# S32K118 register map
Vendor: NXP; Series: S32K; File version: 1.6
CPU: CM0PLUS r0p0, little endian, MPU, FPU, 2 interrupt priority bits
Registers are 32-bit, read-write, reset 0x0 unless marked. A register's access mark holds for its fields unless they carry their own. Offsets are from the block's base; [hi:lo] are bit positions; {n}, {i} and the like mark numbered series; 'fields as' and 'values as' point back to an identical list.

## CSE_PRAM
Base 0x14000800; register names take the prefix CSE_PRAM
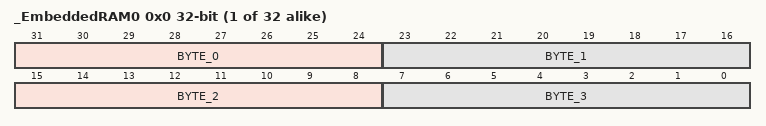
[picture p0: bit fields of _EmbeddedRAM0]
{0x0+4i} _EmbeddedRAM{i} (CSE_PRAM view) (i=0..31) — CSE PRAM {i} Register
  [31-8n:24-8n] BYTE_{n} (n=0..3) — Data byte {n} of Rx/Tx frame.
{0x0+4i} _EmbeddedRAM{i}LL 8-bit (CSE_PRAM view) (i=0..31) — CSE PRAM{i}LL register.
  [7:0] RAM_LL — RAM_LL stores the first 8 bits of the 32 bit CRC
{0x1+4i} _EmbeddedRAM{i}LU 8-bit (i=0..31) — CSE PRAM{i}LU register.
  [7:0] RAM_LU — RAM_LU stores the second 8 bits of the 32 bit CRC
{0x2+4i} _EmbeddedRAM{i}HL 8-bit (i=0..31) — CSE PRAM{i}HL register.
  [7:0] RAM_HL — RAM_HL stores the third 8 bits of the 32 bit CRC
{0x3+4i} _EmbeddedRAM{i}HU 8-bit (i=0..31) — CSE PRAM{i}HU register.
  [7:0] RAM_HU — RAM_HU stores the fourth 8 bits of the 32 bit CRC

## ERM
Base 0x40018000; register names take the prefix ERM_
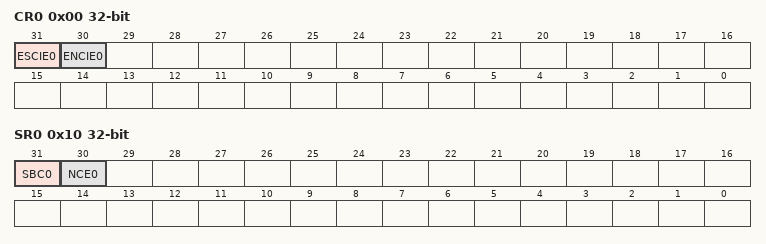
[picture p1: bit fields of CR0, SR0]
0x00 CR0 — ERM Configuration Register 0
  [31] ESCIE0
    0=Interrupt notification of Memory 0 single-bit correction events is disabled; 1=Interrupt notification of Memory 0 single-bit correction events is enabled
  [30] ENCIE0
    0=Interrupt notification of Memory 0 non-correctable error events is disabled; 1=Interrupt notification of Memory 0 non-correctable error events is enabled
0x10 SR0 — ERM Status Register 0
  [31] SBC0
    0=No single-bit correction event on Memory 0 detected; 1=Single-bit correction event on Memory 0 detected
  [30] NCE0
    0=No non-correctable error event on Memory 0 detected; 1=Non-correctable error event on Memory 0 detected
0x100 EAR0 ro — ERM Memory n Error Address Register
  [31:0] EAR

## EIM — Error Injection Module
Base 0x40019000; register names take the prefix EIM_
0x00 EIMCR — Error Injection Module Configuration Register
  [0] GEIEN — Global Error Injection Enable
    0=Disabled; 1=Enabled
0x04 EICHEN — Error Injection Channel Enable register
  [31] EICH0EN — Error Injection Channel 0 Enable
    0=Error injection is disabled on Error Injection Channel 0; 1=Error injection is enabled on Error Injection Channel 0
0x100 EICHD0_WORD0 — Error Injection Channel Descriptor n, Word0
  [31:25] CHKBIT_MASK — Checkbit Mask
0x104 EICHD0_WORD1 — Error Injection Channel Descriptor n, Word1
  [31:0] B0_3DATA_MASK — Data Mask Bytes 0-3

## DMAMUX — DMA channel multiplexor
Base 0x40021000; register names take the prefix DMAMUX_
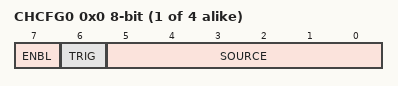
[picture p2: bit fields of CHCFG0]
{0x0+i} CHCFG{i} 8-bit (i=0..3) — Channel Configuration register
  [7] ENBL — DMA Channel Enable
    0=DMA channel is disabled. This mode is primarily used during configuration of the DMAMux. The DMA has separate channel enables/disables, which should be used to disable or reconfigure a DMA channel.; 1=DMA channel is enabled
  [6] TRIG — DMA Channel Trigger Enable
    0=Triggering is disabled. If triggering is disabled and ENBL is set, the DMA Channel will simply route the specified source to the DMA channel. (Normal mode); 1=Triggering is enabled. If triggering is enabled and ENBL is set, the DMAMUX is in Periodic Trigger mode.
  [5:0] SOURCE — DMA Channel Source (Slot)

## CRC — Cyclic Redundancy Check
Base 0x40032000; register names take the prefix CRC_
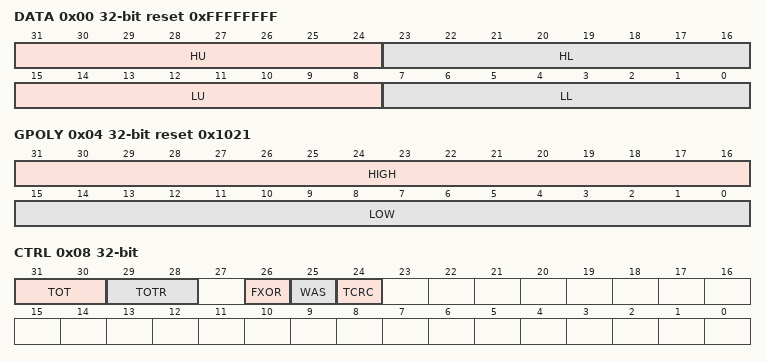
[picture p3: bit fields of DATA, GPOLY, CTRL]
0x00 DATA reset 0xFFFFFFFF (CRC view) — CRC Data register
  [31:24] HU — CRC High Upper Byte
  [23:16] HL — CRC High Lower Byte
  [15:8] LU — CRC Low Upper Byte
  [7:0] LL — CRC Low Lower Byte
0x00 DATAL 16-bit reset 0xFFFF (CRC view) — CRC_DATAL register.
  [15:0] DATAL — DATAL stores the lower 16 bits of the 16/32 bit CRC
0x00 DATALL 8-bit reset 0xFF (CRC view) — CRC_DATALL register.
  [7:0] DATALL — CRCLL stores the first 8 bits of the 32 bit DATA
0x01 DATALU 8-bit reset 0xFF — CRC_DATALU register.
  [7:0] DATALU — DATALL stores the second 8 bits of the 32 bit CRC
0x02 DATAH 16-bit reset 0xFFFF (CRC view) — CRC_DATAH register.
  [15:0] DATAH — DATAH stores the high 16 bits of the 16/32 bit CRC
0x02 DATAHL 8-bit reset 0xFF (CRC view) — CRC_DATAHL register.
  [7:0] DATAHL — DATAHL stores the third 8 bits of the 32 bit CRC
0x03 DATAHU 8-bit reset 0xFF — CRC_DATAHU register.
  [7:0] DATAHU — DATAHU stores the fourth 8 bits of the 32 bit CRC
0x04 GPOLY reset 0x1021 — CRC Polynomial register
  [31:16] HIGH — High Polynominal Half-word
  [15:0] LOW — Low Polynominal Half-word
0x08 CTRL — CRC Control register
  [31:30] TOT — Type Of Transpose For Writes
    0=No transposition; 1=Bits in bytes are transposed; bytes are not transposed; 2=Both bits in bytes and bytes are transposed; 3=Only bytes are transposed; no bits in a byte are transposed
  [29:28] TOTR — Type Of Transpose For Read
    values as TOT
  [26] FXOR — Complement Read Of CRC Data Register
    0=No XOR on reading; 1=Invert or complement the read value of the CRC Data register
  [25] WAS — Write CRC Data Register As Seed
    0=Writes to the CRC data register are data values; 1=Writes to the CRC data register are seed values
  [24] TCRC
    0=16-bit CRC protocol; 1=32-bit CRC protocol
